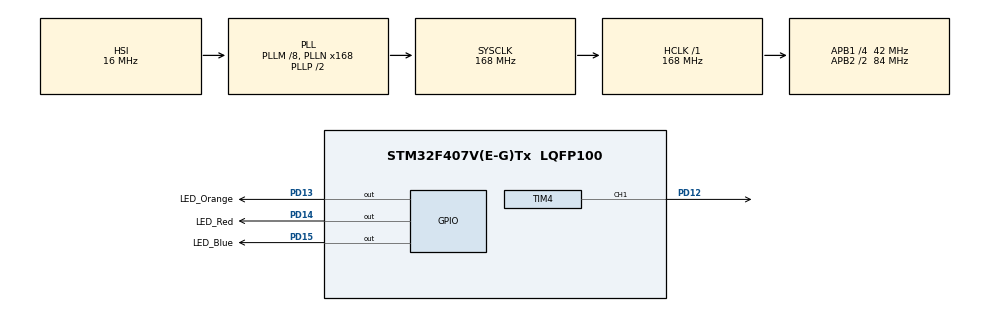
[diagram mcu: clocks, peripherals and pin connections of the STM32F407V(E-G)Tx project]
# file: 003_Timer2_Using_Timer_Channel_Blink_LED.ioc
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Mcu.Family=STM32F4
Mcu.Name=STM32F407V(E-G)Tx
Mcu.Package=LQFP100
NVIC.PriorityGroup=NVIC_PRIORITYGROUP_4
NVIC.TIM4_IRQn=true\:0\:0\:false\:false\:true\:true\:true\:true
PA13.Mode=Trace_Asynchronous_SW
PA13.Signal=SYS_JTMS-SWDIO
PA14.Mode=Trace_Asynchronous_SW
PA14.Signal=SYS_JTCK-SWCLK
PB3.Mode=Trace_Asynchronous_SW
PB3.Signal=SYS_JTDO-SWO
PD12.Signal=S_TIM4_CH1
PD13.GPIO_Label=LED_Orange
PD13.Signal=GPIO_Output
PD14.GPIO_Label=LED_Red
PD14.Signal=GPIO_Output
PD15.GPIO_Label=LED_Blue
PD15.Signal=GPIO_Output
PH0-OSC_IN.Mode=HSE-External-Oscillator
PH0-OSC_IN.Signal=RCC_OSC_IN
PH1-OSC_OUT.Mode=HSE-External-Oscillator
PH1-OSC_OUT.Signal=RCC_OSC_OUT
ProjectManager.HeapSize=0x200
ProjectManager.StackSize=0x400
ProjectManager.TargetToolchain=STM32CubeIDE
RCC.48MHZClocksFreq_Value=84000000
RCC.AHBFreq_Value=168000000
RCC.APB1CLKDivider=RCC_HCLK_DIV4
RCC.APB1Freq_Value=42000000
RCC.APB1TimFreq_Value=84000000
RCC.APB2CLKDivider=RCC_HCLK_DIV2
RCC.APB2Freq_Value=84000000
RCC.APB2TimFreq_Value=168000000
RCC.CortexFreq_Value=168000000
RCC.HCLKFreq_Value=168000000
RCC.HSE_VALUE=8000000
RCC.HSI_VALUE=16000000
RCC.LSE_VALUE=32768
RCC.PLLM=8
RCC.PLLN=168
RCC.SYSCLKFreq_VALUE=168000000
RCC.SYSCLKSource=RCC_SYSCLKSOURCE_PLLCLK
RCC.VCOOutputFreq_Value=336000000
SH.S_TIM4_CH1.0=TIM4_CH1,PWM Generation1 CH1
TIM4.Channel-PWM\ Generation1\ CH1=TIM_CHANNEL_1
TIM4.Period=1399
TIM4.Prescaler=59999
TIM4.Pulse-PWM\ Generation1\ CH1=700
VP_TIM4_VS_ClockSourceINT.Mode=Internal
board=custom

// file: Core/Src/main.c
/* USER CODE BEGIN Header */
/**
  ******************************************************************************
  * @file           : main.c
  * @brief          : Main program body
  ******************************************************************************
  * @attention
  *
  * Copyright (c) 2025 STMicroelectronics.
  * All rights reserved.
  *
  * This software is licensed under terms that can be found in the LICENSE file
  * in the root directory of this software component.
  * If no LICENSE file comes with this software, it is provided AS-IS.
  *
  ******************************************************************************
  */
/* USER CODE END Header */
#include "main.h"

/* USER CODE BEGIN Includes */

#include "stdio.h"

/* USER CODE END Includes */

/* USER CODE BEGIN PD */

#define TICK_DELAY 1000

/* USER CODE END PD */

TIM_HandleTypeDef htim4;

void SystemClock_Config(void);
static void MX_GPIO_Init(void);
static void MX_TIM4_Init(void);
/* USER CODE BEGIN PFP */

// void HAL_TIM_PeriodElapsedCallback(TIM_HandleTypeDef *htim);

/* USER CODE END PFP */

/* USER CODE BEGIN 0 */

int _write(int file, char *ptr, int len) {
  for (int i = 0; i < len; i++) {
    ITM_SendChar(*ptr++);
  }
  return len;
}

/* USER CODE END 0 */

int main(void)
{

  /* MCU Configuration--------------------------------------------------------*/

  /* Reset of all peripherals, Initializes the Flash interface and the Systick. */
  HAL_Init();

  /* Configure the system clock */
  SystemClock_Config();

  /* Initialize all configured peripherals */
  MX_GPIO_Init();
  MX_TIM4_Init();
  /* USER CODE BEGIN 2 */

  printf("\n\n\n\nStarting....");

  // Menyalakan LED lewat PWM
  HAL_TIM_PWM_Start(&htim4, TIM_CHANNEL_1);

  /* USER CODE END 2 */

  /* Infinite loop */
  /* USER CODE BEGIN WHILE */

  uint32_t now = 0;
  uint32_t next_tick = 1000;
  uint32_t loop_count = 0;

  while (1)
  {
    // now = uwTick;
    //
    // if (now >= next_tick) {
    //
    //   printf ("Tick %lu (loop = %lu)\n", now /1000, loop_count);
    //
    //   loop_count = 0;
    //   next_tick = now + 1000;
    //
    // }
    //
    // ++loop_count;
    /* USER CODE END WHILE */

  }
}

void SystemClock_Config(void)
{
  RCC_OscInitTypeDef RCC_OscInitStruct = {0};
  RCC_ClkInitTypeDef RCC_ClkInitStruct = {0};

  /** Configure the main internal regulator output voltage
  */
  __HAL_RCC_PWR_CLK_ENABLE();
  __HAL_PWR_VOLTAGESCALING_CONFIG(PWR_REGULATOR_VOLTAGE_SCALE1);

  /** Initializes the RCC Oscillators according to the specified parameters
  * in the RCC_OscInitTypeDef structure.
  */
  RCC_OscInitStruct.OscillatorType = RCC_OSCILLATORTYPE_HSI;
  RCC_OscInitStruct.HSIState = RCC_HSI_ON;
  RCC_OscInitStruct.HSICalibrationValue = RCC_HSICALIBRATION_DEFAULT;
  RCC_OscInitStruct.PLL.PLLState = RCC_PLL_ON;
  RCC_OscInitStruct.PLL.PLLSource = RCC_PLLSOURCE_HSI;
  RCC_OscInitStruct.PLL.PLLM = 8;
  RCC_OscInitStruct.PLL.PLLN = 168;
  RCC_OscInitStruct.PLL.PLLP = RCC_PLLP_DIV2;
  RCC_OscInitStruct.PLL.PLLQ = 4;
  if (HAL_RCC_OscConfig(&RCC_OscInitStruct) != HAL_OK)
  {
    Error_Handler();
  }

  /** Initializes the CPU, AHB and APB buses clocks
  */
  RCC_ClkInitStruct.ClockType = RCC_CLOCKTYPE_HCLK|RCC_CLOCKTYPE_SYSCLK
                              |RCC_CLOCKTYPE_PCLK1|RCC_CLOCKTYPE_PCLK2;
  RCC_ClkInitStruct.SYSCLKSource = RCC_SYSCLKSOURCE_PLLCLK;
  RCC_ClkInitStruct.AHBCLKDivider = RCC_SYSCLK_DIV1;
  RCC_ClkInitStruct.APB1CLKDivider = RCC_HCLK_DIV4;
  RCC_ClkInitStruct.APB2CLKDivider = RCC_HCLK_DIV2;

  if (HAL_RCC_ClockConfig(&RCC_ClkInitStruct, FLASH_LATENCY_5) != HAL_OK)
  {
    Error_Handler();
  }
}

static void MX_TIM4_Init(void)
{

  TIM_ClockConfigTypeDef sClockSourceConfig = {0};
  TIM_MasterConfigTypeDef sMasterConfig = {0};
  TIM_OC_InitTypeDef sConfigOC = {0};

  htim4.Instance = TIM4;
  htim4.Init.Prescaler = 59999;
  htim4.Init.CounterMode = TIM_COUNTERMODE_UP;
  htim4.Init.Period = 1399;
  htim4.Init.ClockDivision = TIM_CLOCKDIVISION_DIV1;
  htim4.Init.AutoReloadPreload = TIM_AUTORELOAD_PRELOAD_DISABLE;
  if (HAL_TIM_Base_Init(&htim4) != HAL_OK)
  {
    Error_Handler();
  }
  sClockSourceConfig.ClockSource = TIM_CLOCKSOURCE_INTERNAL;
  if (HAL_TIM_ConfigClockSource(&htim4, &sClockSourceConfig) != HAL_OK)
  {
    Error_Handler();
  }
  if (HAL_TIM_PWM_Init(&htim4) != HAL_OK)
  {
    Error_Handler();
  }
  sMasterConfig.MasterOutputTrigger = TIM_TRGO_RESET;
  sMasterConfig.MasterSlaveMode = TIM_MASTERSLAVEMODE_DISABLE;
  if (HAL_TIMEx_MasterConfigSynchronization(&htim4, &sMasterConfig) != HAL_OK)
  {
    Error_Handler();
  }
  sConfigOC.OCMode = TIM_OCMODE_PWM1;
  sConfigOC.Pulse = 700;
  sConfigOC.OCPolarity = TIM_OCPOLARITY_HIGH;
  sConfigOC.OCFastMode = TIM_OCFAST_DISABLE;
  if (HAL_TIM_PWM_ConfigChannel(&htim4, &sConfigOC, TIM_CHANNEL_1) != HAL_OK)
  {
    Error_Handler();
  }
  HAL_TIM_MspPostInit(&htim4);

}

static void MX_GPIO_Init(void)
{
  GPIO_InitTypeDef GPIO_InitStruct = {0};

  /* GPIO Ports Clock Enable */
  __HAL_RCC_GPIOH_CLK_ENABLE();
  __HAL_RCC_GPIOD_CLK_ENABLE();
  __HAL_RCC_GPIOA_CLK_ENABLE();
  __HAL_RCC_GPIOB_CLK_ENABLE();

  /*Configure GPIO pin Output Level */
  HAL_GPIO_WritePin(GPIOD, LED_Orange_Pin|LED_Red_Pin|LED_Blue_Pin, GPIO_PIN_RESET);

  /*Configure GPIO pins : LED_Orange_Pin LED_Red_Pin LED_Blue_Pin */
  GPIO_InitStruct.Pin = LED_Orange_Pin|LED_Red_Pin|LED_Blue_Pin;
  GPIO_InitStruct.Mode = GPIO_MODE_OUTPUT_PP;
  GPIO_InitStruct.Pull = GPIO_NOPULL;
  GPIO_InitStruct.Speed = GPIO_SPEED_FREQ_LOW;
  HAL_GPIO_Init(GPIOD, &GPIO_InitStruct);

}

/* USER CODE BEGIN 4 */

// void HAL_Timex_PeriodElapsedCallback(TIM_HandleTypeDef *htim) {
//   HAL_GPIO_TogglePin(GPIOD, LED_Blue_Pin);
// }

/* USER CODE END 4 */

void Error_Handler(void)
{
  __disable_irq();
  while (1)
  {
  }
}
